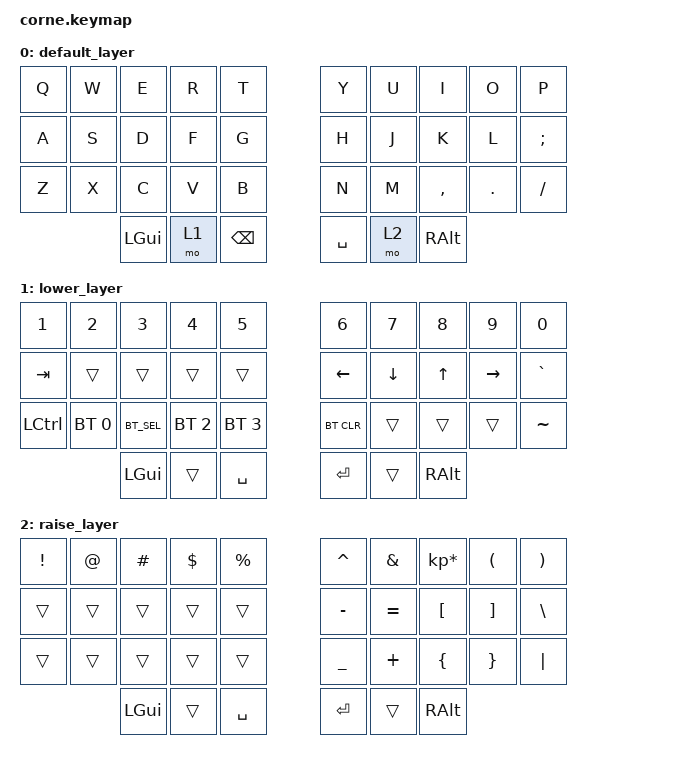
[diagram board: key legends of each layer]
/*
 * Copyright (c) 2020 The ZMK Contributors
 *
 * SPDX-License-Identifier: MIT
 */

#include <behaviors.dtsi>
#include <dt-bindings/zmk/keys.h>
#include <dt-bindings/zmk/bt.h>
// Oops I think I broke it
/ {
        keymap {
                compatible = "zmk,keymap";

                default_layer {
// -----------------------------------------------------------------------------------------
// |  Q  |  W  |  E  |  R  |  T  |   |  Y  |  U   |  I  |  O  |  P  | RET  |
// |  A  |  S  |  D  |  F  |  G  |   |  H  |  J   |  K  |  L  |  ;  |  '   |
// |  Z  |  X  |  C  |  V  |  B  |   |  N  |  M   |  ,  |  .  |  /  | ESC  |
//                    | GUI | LWR | BSPC|   | SPC | RSE  | ALT |
                        bindings = <
   &kp Q &kp W &kp E &kp R &kp T   &kp Y &kp U  &kp I     &kp O   &kp P    
   &kp A &kp S &kp D &kp F &kp G   &kp H &kp J  &kp K     &kp L   &kp SEMI 
   &kp Z &kp X &kp C &kp V &kp B   &kp N &kp M  &kp COMMA &kp DOT &kp FSLH 
                  &kp LGUI &mo 1 &kp BSPC    &kp SPACE &mo 2 &kp RALT
                        >;
                };
                lower_layer {
// -----------------------------------------------------------------------------------------
// |  1  |  2  |  3  |  4  |  5  |   |  6  |  7  |  8  |  9  |  0  |
// | BT1 | BT2 | BT3 | BT4 | BT5 |   | LFT | DWN |  UP | RGT |  `  |
// |CTRL | BT1 | BT2 | BT3 | BT4 |   |BTCLR|     |     |     |  ~  |
//                    | GUI |     | SPC |   | ENT |     | ALT |
                        bindings = <
   &kp N1       &kp N2       &kp N3       &kp N4       &kp N5         &kp N6   &kp N7   &kp N8 &kp N9    &kp N0 
   &kp TAB &trans       &trans       &trans       &trans         &kp LEFT &kp DOWN &kp UP &kp RIGHT &kp GRAVE
   &kp LCTRL   &bt BT_SEL 0  BT_SEL 1 &bt BT_SEL 2 &bt BT_SEL 3         &bt BT_CLR   &trans   &trans &trans    &kp TILDE
                                    &kp LGUI     &trans       &kp SPACE      &kp RET  &trans   &kp RALT
                        >;
                };

                raise_layer {
// -----------------------------------------------------------------------------------------
// |  !  |  @  |  #  |  $  |  %  |   |  ^  |  &  |  *  |  (  |  )  |
// |     |     |     |     |     |   |  -  |  =  |  [  |  ]  |  \  |
// |     |     |     |     |     |   |  _  |  +  |  {  |  }  | "|" |
//                    | GUI |     | SPC |   | ENT |     | ALT |
                        bindings = <
   &kp EXCL &kp AT &kp HASH &kp DLLR &kp PRCNT   &kp CARET &kp AMPS  &kp KP_MULTIPLY &kp LPAR &kp RPAR
   &trans   &trans &trans   &trans   &trans      &kp MINUS &kp EQUAL &kp LBKT        &kp RBKT &kp BSLH
   &trans   &trans &trans   &trans   &trans      &kp UNDER &kp PLUS  &kp LBRC        &kp RBRC &kp PIPE
                             &kp LGUI &trans   &kp SPACE   &kp RET   &trans    &kp RALT
                        >;
                };
        };
};
